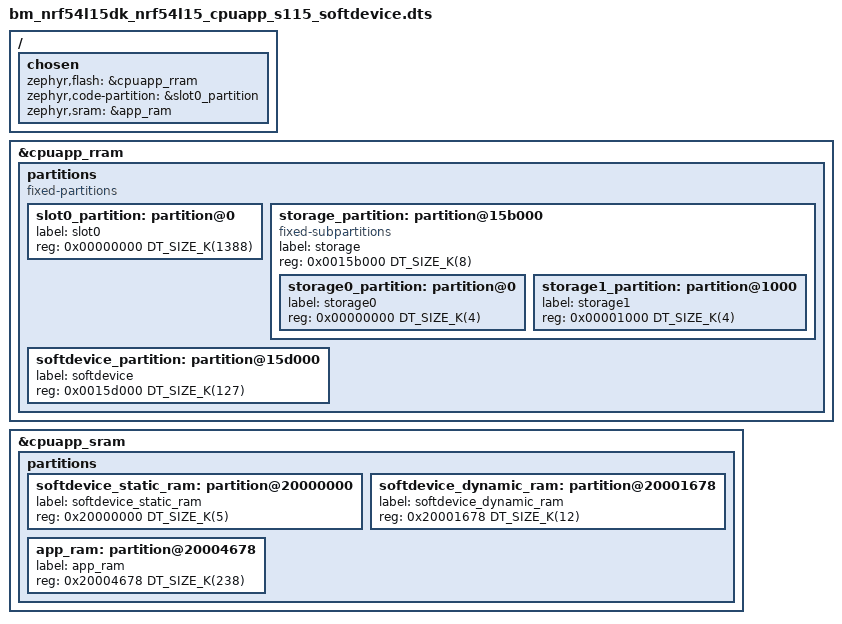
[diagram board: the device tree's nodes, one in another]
/*
 * Copyright (c) 2025 Nordic Semiconductor ASA
 *
 * SPDX-License-Identifier: LicenseRef-Nordic-5-Clause
 */

/dts-v1/;

#include <nordic/nrf54l15_cpuapp.dtsi>
#include "bm_nrf54l15dk_nrf54l15_cpuapp_common.dtsi"

/ {
	chosen {
		zephyr,flash = &cpuapp_rram;
		zephyr,code-partition = &slot0_partition;
		zephyr,sram = &app_ram;
	};
};

&cpuapp_rram {
	status = "okay";

	partitions {
		compatible = "fixed-partitions";
		#address-cells = <1>;
		#size-cells = <1>;

		slot0_partition: partition@0 {
			label = "slot0";
			reg = <0x00000000 DT_SIZE_K(1388)>;
		};

		storage_partition: partition@15b000 {
			compatible = "fixed-subpartitions";
			label = "storage";
			reg = <0x0015b000 DT_SIZE_K(8)>;
			ranges = <0x0 0x15b000 DT_SIZE_K(8)>;
			#address-cells = <1>;
			#size-cells = <1>;

			storage0_partition: partition@0 {
				label = "storage0";
				reg = <0x00000000 DT_SIZE_K(4)>;
			};

			storage1_partition: partition@1000 {
				label = "storage1";
				reg = <0x00001000 DT_SIZE_K(4)>;
			};
		};

		softdevice_partition: partition@15d000 {
			label = "softdevice";
			reg = <0x0015d000 DT_SIZE_K(127)>;
		};
	};
};

&cpuapp_sram {
	status = "okay";

	partitions {
		#address-cells = <1>;
		#size-cells = <1>;

		softdevice_static_ram: partition@20000000 {
			label = "softdevice_static_ram";
			reg = <0x20000000 DT_SIZE_K(5)>;
		};

		softdevice_dynamic_ram: partition@20001678 {
			label = "softdevice_dynamic_ram";
			reg = <0x20001678 DT_SIZE_K(12)>;
		};

		app_ram: partition@20004678 {
			label = "app_ram";
			reg = <0x20004678 DT_SIZE_K(238)>;
		};
	};
};
